AUTOSAR XML (schema 4-0-3)
standard types defined: Boolean, UInt32
package /AUTOSAR_Platform/DataConstrs
  range DC_Boolean: raw 0..1
package /PATAC/Facility/DataTypes/Implementation
  compu method COMPU_Boolean: 0=FALSE, 1=TRUE
  unit NoUnit: factor-si-to-unit=1, offset-si-to-unit=0
package /PATAC/MSM/ComponentTypes
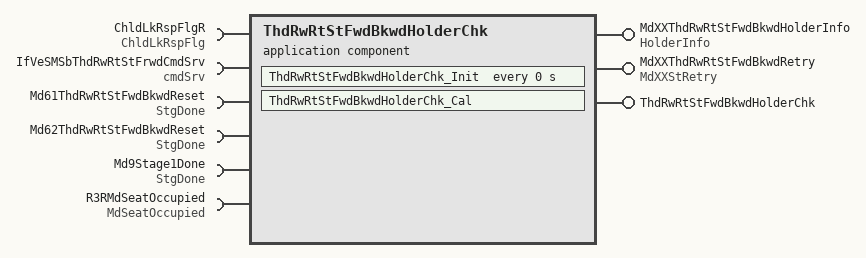
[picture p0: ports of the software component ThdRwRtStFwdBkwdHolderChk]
  application sw component type ThdRwRtStFwdBkwdHolderChk
    provide port MdXXThdRwRtStFwdBkwdHolderInfo: nonqueued-sender-com-spec{data-element=HolderInfo/Val, init-value=0}, provided-interface=HolderInfo
    provide port MdXXThdRwRtStFwdBkwdRetry: nonqueued-sender-com-spec{data-element=MdXXStRetry/Val, init-value=0}, provided-interface=MdXXStRetry
    provide port ThdRwRtStFwdBkwdHolderChk: server-com-spec{operation=Cal, queue-length=1}, provided-interface=ThdRwRtStFwdBkwdHolderChk
    6 x require port:
      ChldLkRspFlgR: nonqueued-receiver-com-spec{data-element=ChldLkRspFlg/Val, filter=data-filter-type=ALWAYS, init-value=0}, required-interface=ChldLkRspFlg
      IfVeSMSbThdRwRtStFrwdCmdSrv: nonqueued-receiver-com-spec{data-element=cmdSrv/Val, filter=data-filter-type=ALWAYS, init-value=1}, required-interface=cmdSrv
      Md61ThdRwRtStFwdBkwdReset: nonqueued-receiver-com-spec{data-element=StgDone/Val, filter=data-filter-type=ALWAYS, init-value=0}, required-interface=StgDone
      Md62ThdRwRtStFwdBkwdReset: nonqueued-receiver-com-spec{data-element=StgDone/Val, filter=data-filter-type=ALWAYS, init-value=0}, required-interface=StgDone
      Md9Stage1Done: nonqueued-receiver-com-spec{data-element=StgDone/Val, filter=data-filter-type=ALWAYS, init-value=0}, required-interface=StgDone
      R3RMdSeatOccupied: nonqueued-receiver-com-spec{data-element=MdSeatOccupied/Val, filter=data-filter-type=ALWAYS, init-value=0}, required-interface=MdSeatOccupied
    behavior ThdRwRtStFwdBkwdHolderChk_InternalBehavior
      operation invoked event OIT_ThdRwRtStFwdBkwdHolderChk_Cal_ThdRwRtStFwdBkwdHolderChk_Cal: start-on-event=ThdRwRtStFwdBkwdHolderChk_Cal, operation=ThdRwRtStFwdBkwdHolderChk.Cal
      timing event ThdRwRtStFwdBkwdHolderChk_InitEvent: start-on-event=ThdRwRtStFwdBkwdHolderChk_Init, period=0
      runnable ThdRwRtStFwdBkwdHolderChk_Cal
        data-receive-point-by-arguments:
          6 x access:
            REC_ChldLkRspFlgR_Val: accessed-variable=ChldLkRspFlgR.Val
            REC_IfVeSMSbThdRwRtStFrwdCmdSrv_Val: accessed-variable=IfVeSMSbThdRwRtStFrwdCmdSrv.Val
            REC_Md61ThdRwRtStFwdBkwdReset_Val: accessed-variable=Md61ThdRwRtStFwdBkwdReset.Val
            REC_Md62ThdRwRtStFwdBkwdReset_Val: accessed-variable=Md62ThdRwRtStFwdBkwdReset.Val
            REC_Md9Stage1Done_Val: accessed-variable=Md9Stage1Done.Val
            REC_R3RMdSeatOccupied_Val: accessed-variable=R3RMdSeatOccupied.Val
        data-send-points:
          access SEND_MdXXThdRwRtStFwdBkwdHolderInfo_Val: accessed-variable=MdXXThdRwRtStFwdBkwdHolderInfo.Val
          access SEND_MdXXThdRwRtStFwdBkwdRetry_Val: accessed-variable=MdXXThdRwRtStFwdBkwdRetry.Val
      runnable ThdRwRtStFwdBkwdHolderChk_Init
  swc implementation ThdRwRtStFwdBkwdHolderChk_Implementation: behavior=ThdRwRtStFwdBkwdHolderChk_InternalBehavior
    code-descriptors:
      code Default: artifact-descriptors=autosar-engineering-object={short-label=Default, category=SWSRC}
package /PATAC/MSM/Intervene/PortInterfaces
  sender receiver interface cmdSrv: invalidation-policy{data-element=cmdSrv/Val, handle-invalid=DONT-INVALIDATE}
    data Val: type=Boolean
package /PATAC/MSM/ModeAdjust/PortInterface
  client server interface ThdRwRtStFwdBkwdHolderChk
    operation Cal
  5 x sender receiver interface:
    ChldLkRspFlg: invalidation-policy{data-element=ChldLkRspFlg/Val, handle-invalid=DONT-INVALIDATE}
      data Val: type=Boolean
    HolderInfo: invalidation-policy{data-element=HolderInfo/Val, handle-invalid=DONT-INVALIDATE}
      data Val: type=UInt32
    MdSeatOccupied: invalidation-policy{data-element=MdSeatOccupied/Val, handle-invalid=DONT-INVALIDATE}
      data Val: type=Boolean
    MdXXStRetry: invalidation-policy{data-element=MdXXStRetry/Val, handle-invalid=DONT-INVALIDATE}
      data Val: type=UInt32
    StgDone: invalidation-policy{data-element=StgDone/Val, handle-invalid=DONT-INVALIDATE}
      data Val: type=Boolean
